VERSION ""

NS_ :

BS_:

BU_:

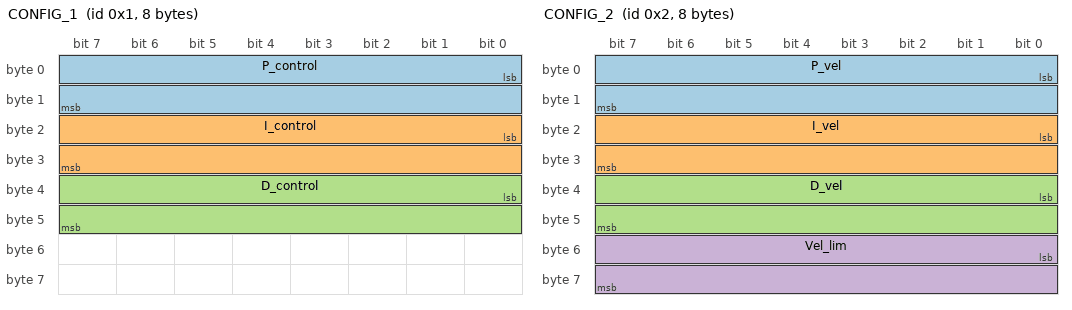
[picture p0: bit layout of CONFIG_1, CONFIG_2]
BO_ 1 CONFIG_1: 8 Vector__XXX
	SG_ P_control : 0|16@1- (0.125,0) [0|8192] "" Vector__XXX
	SG_ I_control : 16|16@1- (0.125,0) [0|8192] "" Vector__XXX
	SG_ D_control : 32|16@1- (0.125,0) [0|8192] "" Vector__XXX

BO_ 2 CONFIG_2: 8 Vector__XXX
	SG_ P_vel : 0|16@1- (0.125,0) [0|8192] "" Vector__XXX
	SG_ I_vel : 16|16@1- (0.125,0) [0|8192] "" Vector__XXX
	SG_ D_vel : 32|16@1- (0.125,0) [0|8192] "" Vector__XXX
	SG_ Vel_lim : 48|16@1- (0.125,0) [0|8192] "" Vector__XXX

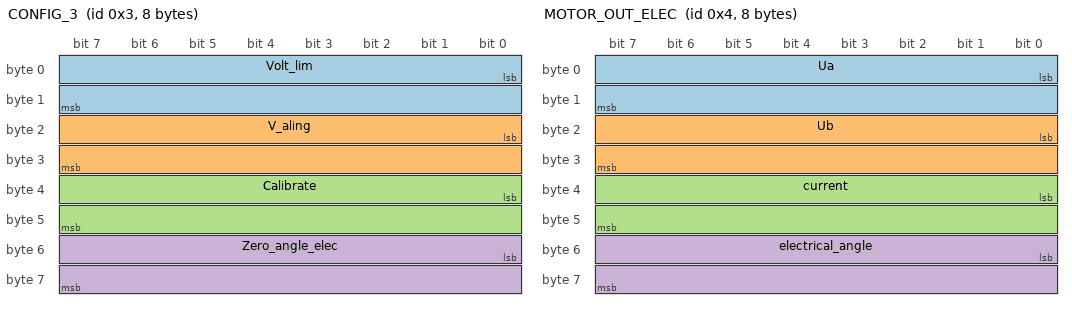
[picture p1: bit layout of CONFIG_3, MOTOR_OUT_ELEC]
BO_ 3 CONFIG_3: 8 Vector__XXX
	SG_ Volt_lim : 0|16@1- (0.125,0) [0|8192] "" Vector__XXX
	SG_ V_aling : 16|16@1- (0.125,0) [0|8192] "" Vector__XXX
	SG_ Calibrate : 32|16@1- (1,0) [0|1] "" Vector__XXX
	SG_ Zero_angle_elec : 48|16@1- (0.125,-4095) [-4096|4096] "" Vector__XXX

BO_ 4 MOTOR_OUT_ELEC: 8 Vector__XXX
	SG_ Ua : 0|16@1- (0.125,-4095) [-4096|4096] "" Vector__XXX
	SG_ Ub : 16|16@1- (0.125,-4095) [-4096|4096] "" Vector__XXX
	SG_ current : 32|16@1- (0.125,-4095) [-4096|4096] "" Vector__XXX
	SG_ electrical_angle : 48|16@1- (0.125,-4095) [-4096|4096] "" Vector__XXX

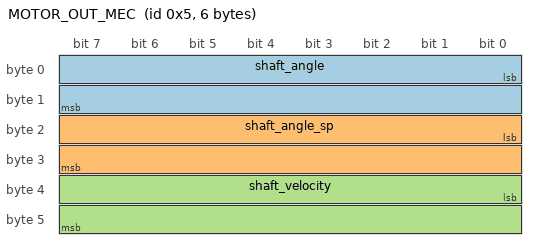
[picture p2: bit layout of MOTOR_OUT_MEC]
BO_ 5 MOTOR_OUT_MEC: 6 Vector__XXX
	SG_ shaft_angle : 0|16@1- (0.125,-4095) [-4096|4096] "" Vector__XXX
	SG_ shaft_angle_sp : 16|16@1- (0.125,-4095) [-4096|4096] "" Vector__XXX
	SG_ shaft_velocity : 32|16@1- (0.125,-4095) [-4096|4096] "" Vector__XXX

BO_ 6 TRANSITION: 2 Vector__XXX
	SG_ Transition : 0|8@1+ (1,0) [0|6] "" Vector__XXX

BO_ 7 MOTOR_ANGLE_SP: 2 Vector__XXX
	SG_ angle_sp : 0|16@1+ (0.125,-4095) [-4096|4096] "" Vector__XXX

CM_ BO_ 1 "Motor config 1";
CM_ BO_ 2 "Motor config 2";
CM_ BO_ 3 "Motor config 3";
CM_ BO_ 4 "Motor electric vars feedback";
CM_ BO_ 5 "Motor mecanic vars feedback";
CM_ BO_ 6 "Motor transition finite state machine";
CM_ BO_ 7 "Motor set point";

BA_DEF_ BO_  "VFrameFormat" ENUM  "StandardCAN","ExtendedCAN","reserved","J1939PG";
BA_DEF_  "DatabaseVersion" STRING ;
BA_DEF_  "BusType" STRING ;
BA_DEF_  "ProtocolType" STRING ;
BA_DEF_  "DatabaseCompiler" STRING ;
BA_DEF_DEF_  "VFrameFormat" "J1939PG";
BA_DEF_DEF_  "DatabaseVersion" "DEMO PLUS";
BA_DEF_DEF_  "BusType" "";
BA_DEF_DEF_  "ProtocolType" "";
BA_DEF_DEF_  "DatabaseCompiler" "";
BA_ "ProtocolType" "J1939";
BA_ "BusType" "CAN";
BA_ "DatabaseCompiler" "CSS ELECTRONICS (WWW.CSSELECTRONICS.COM)";
BA_ "DatabaseVersion" "1.0.0";
